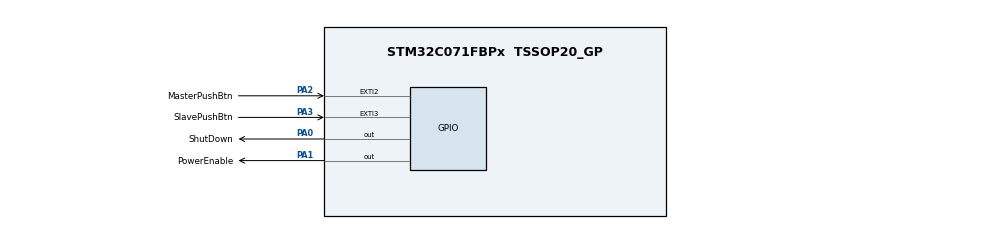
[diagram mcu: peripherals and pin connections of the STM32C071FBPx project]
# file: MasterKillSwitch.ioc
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Mcu.Family=STM32C0
Mcu.Name=STM32C071FBPx
Mcu.Package=TSSOP20_GP
NVIC.EXTI2_3_IRQn=true\:0\:0\:false\:false\:true\:true\:true\:true
NVIC.TIM2_IRQn=true\:0\:0\:false\:false\:true\:true\:true\:true
PA0.GPIO_Label=ShutDown
PA0.GPIO_PuPd=GPIO_PULLDOWN
PA0.Signal=GPIO_Output
PA1.GPIO_Label=PowerEnable
PA1.GPIO_PuPd=GPIO_NOPULL
PA1.PinState=GPIO_PIN_SET
PA1.Signal=GPIO_Output
PA13.Mode=Serial_Wire
PA13.Signal=DEBUG_SWDIO
PA14-BOOT0.Mode=Serial_Wire
PA14-BOOT0.Signal=DEBUG_SWCLK
PA14-BOOT0__PA15.StandardMode=true
PA2.GPIO_Label=MasterPushBtn
PA2.GPIO_PuPd=GPIO_PULLDOWN
PA2.Signal=GPXTI2
PA3.GPIO_Label=SlavePushBtn
PA3.GPIO_ModeDefaultEXTI=GPIO_MODE_IT_FALLING
PA3.Signal=GPXTI3
PB3__PB4__PB5__PB6.StandardMode=true
PB7__PB8.StandardMode=true
ProjectManager.HeapSize=0x200
ProjectManager.StackSize=0x400
ProjectManager.TargetToolchain=CMake
RCC.ADCFreq_Value=48000000
RCC.AHBFreq_Value=48000000
RCC.CortexFreq_Value=48000000
RCC.EXTERNAL_CLOCK_VALUE=12288000
RCC.HCLKFreq_Value=48000000
RCC.HSE_VALUE=8000000
RCC.HSI48_VALUE=48000000
RCC.HSISYSCLKDivider=RCC_HSI_DIV1
RCC.HSI_VALUE=48000000
RCC.LSE_VALUE=32768
RCC.SYSCLKFreq_VALUE=48000000
TIM2.CounterMode=TIM_COUNTERMODE_DOWN
TIM2.Prescaler=48-1
TIM2.TIM_MasterOutputTrigger=TIM_TRGO_UPDATE
VP_TIM2_VS_ClockSourceINT.Mode=Internal
board=custom

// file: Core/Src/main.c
/* USER CODE BEGIN Header */
/**
  ******************************************************************************
  * @file           : main.c
  * @brief          : Main program body
  ******************************************************************************
  * @attention
  *
  * Copyright (c) 2026 STMicroelectronics.
  * All rights reserved.
  *
  * This software is licensed under terms that can be found in the LICENSE file
  * in the root directory of this software component.
  * If no LICENSE file comes with this software, it is provided AS-IS.
  *
  ******************************************************************************
  */
/* USER CODE END Header */
#include "main.h"
#include "stm32c0xx_hal_gpio.h"
#include "stm32c0xx_hal_tim.h"
#include "tim.h"
#include "gpio.h"

/* USER CODE BEGIN PD */
// delay in microseconds after which master relay will get shut down
// 1000us = 1ms
#define MasterRelayShutdownDelayUs 1000
/* USER CODE END PD */

void SystemClock_Config(void);

/* USER CODE BEGIN 0 */

void startPowerOffSequence(void)
{
  // signal external system that we are powering off
  HAL_GPIO_WritePin(ShutDown_GPIO_Port, ShutDown_Pin, GPIO_PIN_SET);
  // start master relay power off countdown
  HAL_TIM_Base_Start_IT(&htim2);
}

void HAL_GPIO_EXTI_Falling_Callback(uint16_t GPIO_Pin)
{
  if (GPIO_Pin == SlavePushBtn_Pin) {
    startPowerOffSequence();
  }
}

void HAL_GPIO_EXTI_Rising_Callback(uint16_t GPIO_Pin)
{
  if (GPIO_Pin == MasterPushBtn_Pin) {
    startPowerOffSequence();
  }
}

void HAL_TIM_PeriodElapsedCallback(TIM_HandleTypeDef *htim)
{
  if (htim->Instance == TIM2)
  {
    // turn off master relay
    HAL_GPIO_WritePin(PowerEnable_GPIO_Port, PowerEnable_Pin, GPIO_PIN_RESET);
  }
}
/* USER CODE END 0 */

int main(void)
{

  /* MCU Configuration--------------------------------------------------------*/

  /* Reset of all peripherals, Initializes the Flash interface and the Systick. */
  HAL_Init();

  /* Configure the system clock */
  SystemClock_Config();

  /* Initialize all configured peripherals */
  MX_GPIO_Init();
  MX_TIM2_Init();
  /* USER CODE BEGIN 2 */
  __HAL_TIM_SET_COUNTER(&htim2, MasterRelayShutdownDelayUs);
  /* USER CODE END 2 */

  /* Infinite loop */
  while (1)
  {

  }
}

void SystemClock_Config(void)
{
  RCC_OscInitTypeDef RCC_OscInitStruct = {0};
  RCC_ClkInitTypeDef RCC_ClkInitStruct = {0};

  __HAL_FLASH_SET_LATENCY(FLASH_LATENCY_1);

  /** Initializes the RCC Oscillators according to the specified parameters
  * in the RCC_OscInitTypeDef structure.
  */
  RCC_OscInitStruct.OscillatorType = RCC_OSCILLATORTYPE_HSI;
  RCC_OscInitStruct.HSIState = RCC_HSI_ON;
  RCC_OscInitStruct.HSIDiv = RCC_HSI_DIV1;
  RCC_OscInitStruct.HSICalibrationValue = RCC_HSICALIBRATION_DEFAULT;
  if (HAL_RCC_OscConfig(&RCC_OscInitStruct) != HAL_OK)
  {
    Error_Handler();
  }

  /** Initializes the CPU, AHB and APB buses clocks
  */
  RCC_ClkInitStruct.ClockType = RCC_CLOCKTYPE_HCLK|RCC_CLOCKTYPE_SYSCLK
                              |RCC_CLOCKTYPE_PCLK1;
  RCC_ClkInitStruct.SYSCLKSource = RCC_SYSCLKSOURCE_HSI;
  RCC_ClkInitStruct.SYSCLKDivider = RCC_SYSCLK_DIV1;
  RCC_ClkInitStruct.AHBCLKDivider = RCC_HCLK_DIV1;
  RCC_ClkInitStruct.APB1CLKDivider = RCC_APB1_DIV1;

  if (HAL_RCC_ClockConfig(&RCC_ClkInitStruct, FLASH_LATENCY_1) != HAL_OK)
  {
    Error_Handler();
  }
}

void Error_Handler(void)
{
  __disable_irq();
  while (1)
  {
  }
}
